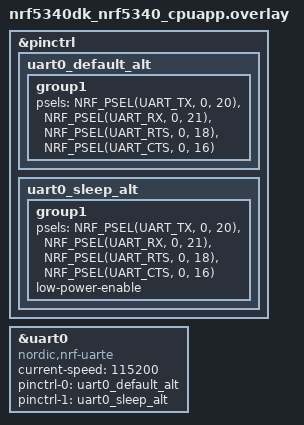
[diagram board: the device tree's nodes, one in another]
/* SPDX-License-Identifier: Apache-2.0 */

&pinctrl {
	uart0_default_alt: uart0_default_alt {
	   group1 {
		  psels = <NRF_PSEL(UART_TX, 0, 20)>,
				  <NRF_PSEL(UART_RX, 0, 21)>,
				  <NRF_PSEL(UART_RTS, 0, 18)>,
				  <NRF_PSEL(UART_CTS, 0, 16)>;
	   };
	};
 
	uart0_sleep_alt: uart0_sleep_alt {
	   group1 {
		  psels = <NRF_PSEL(UART_TX, 0, 20)>,
				  <NRF_PSEL(UART_RX, 0, 21)>,
				  <NRF_PSEL(UART_RTS, 0, 18)>,
				  <NRF_PSEL(UART_CTS, 0, 16)>;
		  low-power-enable;
	   };
	};
 };
 
 &uart0 {
	status = "okay";
	compatible = "nordic,nrf-uarte";
	current-speed = <115200>;
	pinctrl-0 = <&uart0_default_alt>;
	pinctrl-1 = <&uart0_sleep_alt>;
	pinctrl-names = "default", "sleep";
	/* hw-flow-control; */
 };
